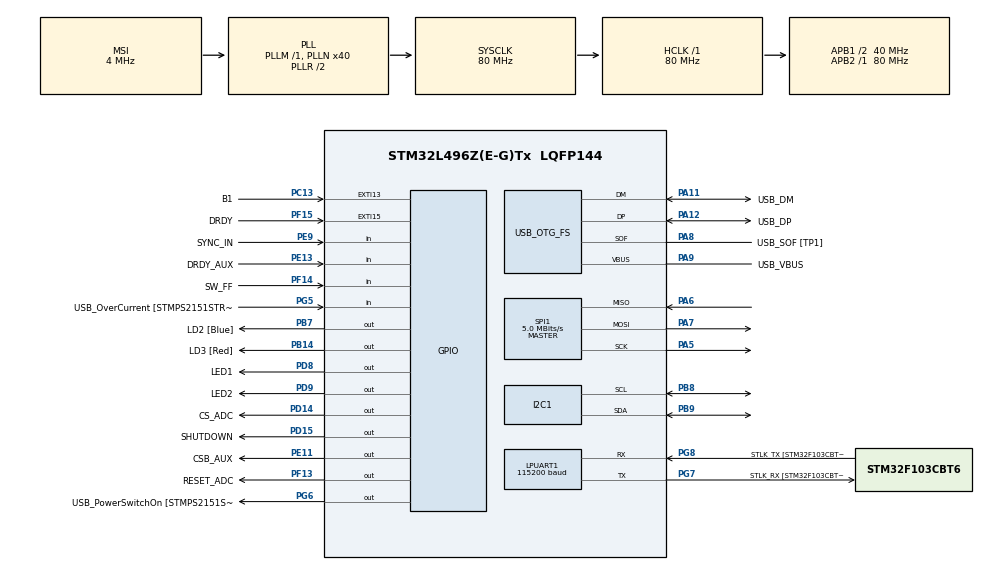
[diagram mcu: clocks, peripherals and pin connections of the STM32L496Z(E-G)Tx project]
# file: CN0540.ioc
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Dma.Request0=SPI1_RX
Dma.Request1=SPI1_TX
Dma.SPI1_RX.0.Direction=DMA_PERIPH_TO_MEMORY
Dma.SPI1_RX.0.Instance=DMA1_Channel2
Dma.SPI1_RX.0.MemDataAlignment=DMA_MDATAALIGN_BYTE
Dma.SPI1_RX.0.MemInc=DMA_MINC_ENABLE
Dma.SPI1_RX.0.Mode=DMA_NORMAL
Dma.SPI1_RX.0.PeriphDataAlignment=DMA_PDATAALIGN_BYTE
Dma.SPI1_RX.0.PeriphInc=DMA_PINC_DISABLE
Dma.SPI1_RX.0.Priority=DMA_PRIORITY_LOW
Dma.SPI1_TX.1.Direction=DMA_MEMORY_TO_PERIPH
Dma.SPI1_TX.1.Instance=DMA1_Channel3
Dma.SPI1_TX.1.MemDataAlignment=DMA_MDATAALIGN_BYTE
Dma.SPI1_TX.1.MemInc=DMA_MINC_ENABLE
Dma.SPI1_TX.1.Mode=DMA_NORMAL
Dma.SPI1_TX.1.PeriphDataAlignment=DMA_PDATAALIGN_BYTE
Dma.SPI1_TX.1.PeriphInc=DMA_PINC_DISABLE
Dma.SPI1_TX.1.Priority=DMA_PRIORITY_LOW
I2C1.Timing=0x00909BEB
LPUART1.BaudRate=115200
LPUART1.WordLength=UART_WORDLENGTH_8B
Mcu.Family=STM32L4
Mcu.Name=STM32L496Z(E-G)Tx
Mcu.Package=LQFP144
NVIC.DMA1_Channel2_IRQn=true\:0\:0\:false\:false\:true\:false\:true\:true
NVIC.DMA1_Channel3_IRQn=true\:0\:0\:false\:false\:true\:false\:true\:true
NVIC.EXTI15_10_IRQn=true\:0\:0\:false\:false\:true\:true\:true\:true
NVIC.I2C1_ER_IRQn=true\:0\:0\:false\:false\:true\:true\:true\:true
NVIC.I2C1_EV_IRQn=true\:0\:0\:false\:false\:true\:true\:true\:true
NVIC.LPUART1_IRQn=true\:0\:0\:false\:false\:true\:true\:true\:true
NVIC.PriorityGroup=NVIC_PRIORITYGROUP_4
PA10.GPIO_Label=USB_ID
PA10.Signal=USB_OTG_FS_ID
PA11.GPIO_Label=USB_DM
PA11.Mode=Device_Only
PA11.Signal=USB_OTG_FS_DM
PA12.GPIO_Label=USB_DP
PA12.Mode=Device_Only
PA12.Signal=USB_OTG_FS_DP
PA13\ (JTMS/SWDIO).GPIO_Label=TMS
PA13\ (JTMS/SWDIO).Mode=Trace_Asynchronous_SW
PA13\ (JTMS/SWDIO).Signal=SYS_JTMS-SWDIO
PA14\ (JTCK/SWCLK).GPIO_Label=TCK
PA14\ (JTCK/SWCLK).Mode=Trace_Asynchronous_SW
PA14\ (JTCK/SWCLK).Signal=SYS_JTCK-SWCLK
PA3.GPIO_Label=IO5
PA3.Signal=ADCx_IN8
PA5.GPIO_Speed=GPIO_SPEED_FREQ_HIGH
PA5.Mode=Full_Duplex_Master
PA5.Signal=SPI1_SCK
PA6.GPIO_Speed=GPIO_SPEED_FREQ_HIGH
PA6.Mode=Full_Duplex_Master
PA6.Signal=SPI1_MISO
PA7.GPIO_Speed=GPIO_SPEED_FREQ_HIGH
PA7.Mode=Full_Duplex_Master
PA7.Signal=SPI1_MOSI
PA8.GPIO_Label=USB_SOF [TP1]
PA8.Mode=Activate_SOF_FS
PA8.Signal=USB_OTG_FS_SOF
PA9.GPIO_Label=USB_VBUS
PA9.Mode=Activate_VBUS
PA9.Signal=USB_OTG_FS_VBUS
PB14.GPIO_Label=LD3 [Red]
PB14.Signal=GPIO_Output
PB3\ (JTDO/TRACESWO).GPIO_Label=SWO
PB3\ (JTDO/TRACESWO).Mode=Trace_Asynchronous_SW
PB3\ (JTDO/TRACESWO).Signal=SYS_JTDO-SWO
PB7.GPIO_Label=LD2 [Blue]
PB7.Signal=GPIO_Output
PB8.Mode=I2C
PB8.Signal=I2C1_SCL
PB9.Mode=I2C
PB9.Signal=I2C1_SDA
PC0.GPIO_Label=IO4
PC0.Signal=ADCx_IN1
PC13.GPIO_Label=B1
PC13.Signal=GPXTI13
PC14-OSC32_IN\ (PC14).Mode=LSE-External-Oscillator
PC14-OSC32_IN\ (PC14).Signal=RCC_OSC32_IN
PC15-OSC32_OUT\ (PC15).Mode=LSE-External-Oscillator
PC15-OSC32_OUT\ (PC15).Signal=RCC_OSC32_OUT
PC3.GPIO_Label=IO3
PC3.Signal=ADCx_IN4
PC5.GPIO_Label=IO0
PC5.Signal=ADCx_IN14
PD14.GPIO_Label=CS_ADC
PD14.PinState=GPIO_PIN_SET
PD14.Signal=GPIO_Output
PD15.GPIO_Label=SHUTDOWN
PD15.PinState=GPIO_PIN_SET
PD15.Signal=GPIO_Output
PD8.GPIO_Label=LED1
PD8.Signal=GPIO_Output
PD9.GPIO_Label=LED2
PD9.Signal=GPIO_Output
PE11.GPIO_Label=CSB_AUX
PE11.Signal=GPIO_Output
PE13.GPIO_Label=DRDY_AUX
PE13.Signal=GPIO_Input
PE9.GPIO_Label=SYNC_IN
PE9.Signal=GPIO_Input
PF13.GPIO_Label=RESET_ADC
PF13.GPIO_ModeDefaultOutputPP=GPIO_MODE_OUTPUT_OD
PF13.GPIO_PuPd=GPIO_NOPULL
PF13.PinState=GPIO_PIN_SET
PF13.Signal=GPIO_Output
PF14.GPIO_Label=SW_FF
PF14.Signal=GPIO_Input
PF15.GPIO_Label=DRDY
PF15.GPIO_ModeDefaultEXTI=GPIO_MODE_IT_FALLING
PF15.Signal=GPXTI15
PG5.GPIO_Label=USB_OverCurrent [STMPS2151STR_FAULT]
PG5.Signal=GPIO_Input
PG6.GPIO_Label=USB_PowerSwitchOn [STMPS2151STR_EN]
PG6.Signal=GPIO_Output
PG7.GPIO_Label=STLK_RX [STM32F103CBT6_PA3]
PG7.Mode=Asynchronous
PG7.Signal=LPUART1_TX
PG8.GPIO_Label=STLK_TX [STM32F103CBT6_PA2]
PG8.Mode=Asynchronous
PG8.Signal=LPUART1_RX
PH1-OSC_OUT\ (PH1).Signal=RCC_OSC_OUT
ProjectManager.HeapSize=0x200
ProjectManager.StackSize=0x400
ProjectManager.TargetToolchain=STM32CubeIDE
RCC.48MHZClocksFreq_Value=24000000
RCC.ADCFreq_Value=48000000
RCC.AHBFreq_Value=80000000
RCC.APB1CLKDivider=RCC_HCLK_DIV2
RCC.APB1Freq_Value=40000000
RCC.APB1TimFreq_Value=80000000
RCC.APB2Freq_Value=80000000
RCC.APB2TimFreq_Value=80000000
RCC.CortexFreq_Value=80000000
RCC.HCLKFreq_Value=80000000
RCC.HSE_VALUE=8000000
RCC.HSI48_VALUE=48000000
RCC.HSI_VALUE=16000000
RCC.MSI_VALUE=4000000
RCC.PLLMUL=RCC_PLL_MUL9
RCC.PLLN=40
RCC.PLLSAI1N=24
RCC.PRESCALERUSB=RCC_USBCLKSOURCE_PLL_DIV1_5
RCC.SYSCLKFreq_VALUE=80000000
RCC.SYSCLKSource=RCC_SYSCLKSOURCE_PLLCLK
RCC.SYSCLKSourceVirtual=RCC_SYSCLKSOURCE_PLLCLK
RCC.USBFreq_Value=48000000
RCC.VCOOutputFreq_Value=160000000
SH.ADCx_IN1.0=ADC1_IN1
SH.ADCx_IN14.0=ADC1_IN14
SH.ADCx_IN4.0=ADC1_IN4
SH.ADCx_IN8.0=ADC1_IN8
SPI1.BaudRatePrescaler=SPI_BAUDRATEPRESCALER_16
SPI1.CLKPhase=SPI_PHASE_2EDGE
SPI1.CLKPolarity=SPI_POLARITY_HIGH
SPI1.CalculateBaudRate=5.0 MBits/s
SPI1.DataSize=SPI_DATASIZE_8BIT
SPI1.Direction=SPI_DIRECTION_2LINES
SPI1.Mode=SPI_MODE_MASTER
SPI1.VirtualType=VM_MASTER
USB_OTG_FS.VirtualMode=Device_Only
VP_TIM3_VS_ClockSourceINT.Mode=Internal
board=NUCLEO-L496ZG

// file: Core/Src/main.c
/* USER CODE BEGIN Header */
/**
  ******************************************************************************
  * @file           : main.c
  * @brief          : Main program body
  ******************************************************************************
  * @attention
  *
  * Copyright (c) 2022 STMicroelectronics.
  * All rights reserved.
  *
  * This software is licensed under terms that can be found in the LICENSE file
  * in the root directory of this software component.
  * If no LICENSE file comes with this software, it is provided AS-IS.
  *
  ******************************************************************************
  */
/* USER CODE END Header */
#include "main.h"

/* USER CODE BEGIN Includes */
#include "cn0540_main.h"

/* USER CODE END Includes */

I2C_HandleTypeDef hi2c1;

SPI_HandleTypeDef hspi1;
DMA_HandleTypeDef hdma_spi1_rx;
DMA_HandleTypeDef hdma_spi1_tx;

PCD_HandleTypeDef hpcd_USB_OTG_FS;

void SystemClock_Config(void);
static void MX_GPIO_Init(void);
static void MX_DMA_Init(void);
static void MX_LPUART1_UART_Init(void);
static void MX_USB_OTG_FS_PCD_Init(void);
static void MX_I2C1_Init(void);
static void MX_SPI1_Init(void);
static void MX_TIM3_Init(void);

int main(void)
{

  /* MCU Configuration--------------------------------------------------------*/

  /* Reset of all peripherals, Initializes the Flash interface and the Systick. */
  HAL_Init();

  /* Configure the system clock */
  SystemClock_Config();

  /* Initialize all configured peripherals */
  MX_GPIO_Init();
  MX_DMA_Init();
  MX_LPUART1_UART_Init();
  MX_USB_OTG_FS_PCD_Init();
  MX_I2C1_Init();
  MX_SPI1_Init();
  MX_TIM3_Init();
  /* USER CODE BEGIN 2 */

  cn0540_main();

  /* USER CODE END 2 */

  /* Infinite loop */

}

void SystemClock_Config(void)
{
  RCC_OscInitTypeDef RCC_OscInitStruct = {0};
  RCC_ClkInitTypeDef RCC_ClkInitStruct = {0};

  /** Configure the main internal regulator output voltage
  */
  if (HAL_PWREx_ControlVoltageScaling(PWR_REGULATOR_VOLTAGE_SCALE1) != HAL_OK)
  {
    Error_Handler();
  }

  /** Configure LSE Drive Capability
  */
  HAL_PWR_EnableBkUpAccess();
  __HAL_RCC_LSEDRIVE_CONFIG(RCC_LSEDRIVE_LOW);

  /** Initializes the RCC Oscillators according to the specified parameters
  * in the RCC_OscInitTypeDef structure.
  */
  RCC_OscInitStruct.OscillatorType = RCC_OSCILLATORTYPE_LSE|RCC_OSCILLATORTYPE_MSI;
  RCC_OscInitStruct.LSEState = RCC_LSE_ON;
  RCC_OscInitStruct.MSIState = RCC_MSI_ON;
  RCC_OscInitStruct.MSICalibrationValue = 0;
  RCC_OscInitStruct.MSIClockRange = RCC_MSIRANGE_6;
  RCC_OscInitStruct.PLL.PLLState = RCC_PLL_ON;
  RCC_OscInitStruct.PLL.PLLSource = RCC_PLLSOURCE_MSI;
  RCC_OscInitStruct.PLL.PLLM = 1;
  RCC_OscInitStruct.PLL.PLLN = 40;
  RCC_OscInitStruct.PLL.PLLP = RCC_PLLP_DIV2;
  RCC_OscInitStruct.PLL.PLLQ = RCC_PLLQ_DIV2;
  RCC_OscInitStruct.PLL.PLLR = RCC_PLLR_DIV2;
  if (HAL_RCC_OscConfig(&RCC_OscInitStruct) != HAL_OK)
  {
    Error_Handler();
  }

  /** Initializes the CPU, AHB and APB buses clocks
  */
  RCC_ClkInitStruct.ClockType = RCC_CLOCKTYPE_HCLK|RCC_CLOCKTYPE_SYSCLK
                              |RCC_CLOCKTYPE_PCLK1|RCC_CLOCKTYPE_PCLK2;
  RCC_ClkInitStruct.SYSCLKSource = RCC_SYSCLKSOURCE_PLLCLK;
  RCC_ClkInitStruct.AHBCLKDivider = RCC_SYSCLK_DIV1;
  RCC_ClkInitStruct.APB1CLKDivider = RCC_HCLK_DIV2;
  RCC_ClkInitStruct.APB2CLKDivider = RCC_HCLK_DIV1;

  if (HAL_RCC_ClockConfig(&RCC_ClkInitStruct, FLASH_LATENCY_4) != HAL_OK)
  {
    Error_Handler();
  }

  /** Enable MSI Auto calibration
  */
  HAL_RCCEx_EnableMSIPLLMode();
}

static void MX_I2C1_Init(void)
{

  hi2c1.Instance = I2C1;
  hi2c1.Init.Timing = 0x00909BEB;
  hi2c1.Init.OwnAddress1 = 0;
  hi2c1.Init.AddressingMode = I2C_ADDRESSINGMODE_7BIT;
  hi2c1.Init.DualAddressMode = I2C_DUALADDRESS_DISABLE;
  hi2c1.Init.OwnAddress2 = 0;
  hi2c1.Init.OwnAddress2Masks = I2C_OA2_NOMASK;
  hi2c1.Init.GeneralCallMode = I2C_GENERALCALL_DISABLE;
  hi2c1.Init.NoStretchMode = I2C_NOSTRETCH_DISABLE;
  if (HAL_I2C_Init(&hi2c1) != HAL_OK)
  {
    Error_Handler();
  }

  /** Configure Analogue filter
  */
  if (HAL_I2CEx_ConfigAnalogFilter(&hi2c1, I2C_ANALOGFILTER_ENABLE) != HAL_OK)
  {
    Error_Handler();
  }

  /** Configure Digital filter
  */
  if (HAL_I2CEx_ConfigDigitalFilter(&hi2c1, 0) != HAL_OK)
  {
    Error_Handler();
  }

}

static void MX_LPUART1_UART_Init(void)
{

  LL_LPUART_InitTypeDef LPUART_InitStruct = {0};

  LL_GPIO_InitTypeDef GPIO_InitStruct = {0};
  RCC_PeriphCLKInitTypeDef PeriphClkInit = {0};

  /** Initializes the peripherals clock
  */
  PeriphClkInit.PeriphClockSelection = RCC_PERIPHCLK_LPUART1;
  PeriphClkInit.Lpuart1ClockSelection = RCC_LPUART1CLKSOURCE_PCLK1;
  if (HAL_RCCEx_PeriphCLKConfig(&PeriphClkInit) != HAL_OK)
  {
    Error_Handler();
  }

  /* Peripheral clock enable */
  LL_APB1_GRP2_EnableClock(LL_APB1_GRP2_PERIPH_LPUART1);

  LL_AHB2_GRP1_EnableClock(LL_AHB2_GRP1_PERIPH_GPIOG);
  HAL_PWREx_EnableVddIO2();
  /**LPUART1 GPIO Configuration
  PG7   ------> LPUART1_TX
  PG8   ------> LPUART1_RX
  */
  GPIO_InitStruct.Pin = LL_GPIO_PIN_7|LL_GPIO_PIN_8;
  GPIO_InitStruct.Mode = LL_GPIO_MODE_ALTERNATE;
  GPIO_InitStruct.Speed = LL_GPIO_SPEED_FREQ_VERY_HIGH;
  GPIO_InitStruct.OutputType = LL_GPIO_OUTPUT_PUSHPULL;
  GPIO_InitStruct.Pull = LL_GPIO_PULL_NO;
  GPIO_InitStruct.Alternate = LL_GPIO_AF_8;
  LL_GPIO_Init(GPIOG, &GPIO_InitStruct);

  /* LPUART1 interrupt Init */
  NVIC_SetPriority(LPUART1_IRQn, NVIC_EncodePriority(NVIC_GetPriorityGrouping(),0, 0));
  NVIC_EnableIRQ(LPUART1_IRQn);

  LPUART_InitStruct.BaudRate = 115200;
  LPUART_InitStruct.DataWidth = LL_LPUART_DATAWIDTH_8B;
  LPUART_InitStruct.StopBits = LL_LPUART_STOPBITS_1;
  LPUART_InitStruct.Parity = LL_LPUART_PARITY_NONE;
  LPUART_InitStruct.TransferDirection = LL_LPUART_DIRECTION_TX_RX;
  LPUART_InitStruct.HardwareFlowControl = LL_LPUART_HWCONTROL_NONE;
  LL_LPUART_Init(LPUART1, &LPUART_InitStruct);
  LL_LPUART_Enable(LPUART1);
  /* USER CODE BEGIN LPUART1_Init 2 */

  LL_LPUART_ClearFlag_PE(LPUART1);
  LL_LPUART_ClearFlag_FE(LPUART1);
  LL_LPUART_ClearFlag_NE(LPUART1);
  LL_LPUART_ClearFlag_ORE(LPUART1);
  LL_LPUART_EnableIT_RXNE(LPUART1);

  /* USER CODE END LPUART1_Init 2 */

}

static void MX_SPI1_Init(void)
{

  /* SPI1 parameter configuration*/
  hspi1.Instance = SPI1;
  hspi1.Init.Mode = SPI_MODE_MASTER;
  hspi1.Init.Direction = SPI_DIRECTION_2LINES;
  hspi1.Init.DataSize = SPI_DATASIZE_8BIT;
  hspi1.Init.CLKPolarity = SPI_POLARITY_HIGH;
  hspi1.Init.CLKPhase = SPI_PHASE_2EDGE;
  hspi1.Init.NSS = SPI_NSS_SOFT;
  hspi1.Init.BaudRatePrescaler = SPI_BAUDRATEPRESCALER_16;
  hspi1.Init.FirstBit = SPI_FIRSTBIT_MSB;
  hspi1.Init.TIMode = SPI_TIMODE_DISABLE;
  hspi1.Init.CRCCalculation = SPI_CRCCALCULATION_DISABLE;
  hspi1.Init.CRCPolynomial = 7;
  hspi1.Init.CRCLength = SPI_CRC_LENGTH_DATASIZE;
  hspi1.Init.NSSPMode = SPI_NSS_PULSE_DISABLE;
  if (HAL_SPI_Init(&hspi1) != HAL_OK)
  {
    Error_Handler();
  }

}

static void MX_TIM3_Init(void)
{

  LL_TIM_InitTypeDef TIM_InitStruct = {0};

  /* Peripheral clock enable */
  LL_APB1_GRP1_EnableClock(LL_APB1_GRP1_PERIPH_TIM3);

  TIM_InitStruct.Prescaler = 0;
  TIM_InitStruct.CounterMode = LL_TIM_COUNTERMODE_UP;
  TIM_InitStruct.Autoreload = 65535;
  TIM_InitStruct.ClockDivision = LL_TIM_CLOCKDIVISION_DIV1;
  LL_TIM_Init(TIM3, &TIM_InitStruct);
  LL_TIM_DisableARRPreload(TIM3);
  LL_TIM_SetClockSource(TIM3, LL_TIM_CLOCKSOURCE_INTERNAL);
  LL_TIM_SetTriggerOutput(TIM3, LL_TIM_TRGO_RESET);
  LL_TIM_DisableMasterSlaveMode(TIM3);

}

static void MX_USB_OTG_FS_PCD_Init(void)
{

  hpcd_USB_OTG_FS.Instance = USB_OTG_FS;
  hpcd_USB_OTG_FS.Init.dev_endpoints = 6;
  hpcd_USB_OTG_FS.Init.speed = PCD_SPEED_FULL;
  hpcd_USB_OTG_FS.Init.phy_itface = PCD_PHY_EMBEDDED;
  hpcd_USB_OTG_FS.Init.Sof_enable = ENABLE;
  hpcd_USB_OTG_FS.Init.low_power_enable = DISABLE;
  hpcd_USB_OTG_FS.Init.lpm_enable = DISABLE;
  hpcd_USB_OTG_FS.Init.battery_charging_enable = ENABLE;
  hpcd_USB_OTG_FS.Init.use_dedicated_ep1 = DISABLE;
  hpcd_USB_OTG_FS.Init.vbus_sensing_enable = ENABLE;
  if (HAL_PCD_Init(&hpcd_USB_OTG_FS) != HAL_OK)
  {
    Error_Handler();
  }

}

static void MX_DMA_Init(void)
{

  /* DMA controller clock enable */
  __HAL_RCC_DMA1_CLK_ENABLE();

  /* DMA interrupt init */
  /* DMA1_Channel2_IRQn interrupt configuration */
  HAL_NVIC_SetPriority(DMA1_Channel2_IRQn, 0, 0);
  HAL_NVIC_EnableIRQ(DMA1_Channel2_IRQn);
  /* DMA1_Channel3_IRQn interrupt configuration */
  HAL_NVIC_SetPriority(DMA1_Channel3_IRQn, 0, 0);
  HAL_NVIC_EnableIRQ(DMA1_Channel3_IRQn);

}

static void MX_GPIO_Init(void)
{
  GPIO_InitTypeDef GPIO_InitStruct = {0};

  /* GPIO Ports Clock Enable */
  __HAL_RCC_GPIOE_CLK_ENABLE();
  __HAL_RCC_GPIOC_CLK_ENABLE();
  __HAL_RCC_GPIOF_CLK_ENABLE();
  __HAL_RCC_GPIOH_CLK_ENABLE();
  __HAL_RCC_GPIOA_CLK_ENABLE();
  __HAL_RCC_GPIOB_CLK_ENABLE();
  __HAL_RCC_GPIOG_CLK_ENABLE();
  __HAL_RCC_GPIOD_CLK_ENABLE();
  HAL_PWREx_EnableVddIO2();

  /*Configure GPIO pin Output Level */
  HAL_GPIO_WritePin(RESET_ADC_GPIO_Port, RESET_ADC_Pin, GPIO_PIN_SET);

  /*Configure GPIO pin Output Level */
  HAL_GPIO_WritePin(CSB_AUX_GPIO_Port, CSB_AUX_Pin, GPIO_PIN_RESET);

  /*Configure GPIO pin Output Level */
  HAL_GPIO_WritePin(GPIOB, LD3_Pin|LD2_Pin, GPIO_PIN_RESET);

  /*Configure GPIO pin Output Level */
  HAL_GPIO_WritePin(GPIOD, LED1_Pin|LED2_Pin, GPIO_PIN_RESET);

  /*Configure GPIO pin Output Level */
  HAL_GPIO_WritePin(GPIOD, CS_ADC_Pin|SHUTDOWN_Pin, GPIO_PIN_SET);

  /*Configure GPIO pin Output Level */
  HAL_GPIO_WritePin(USB_PowerSwitchOn_GPIO_Port, USB_PowerSwitchOn_Pin, GPIO_PIN_RESET);

  /*Configure GPIO pins : PE2 PE3 PE4 PE5
                           PE6 PE7 PE8 PE10
                           PE12 PE14 PE15 PE0
                           PE1 */
  GPIO_InitStruct.Pin = GPIO_PIN_2|GPIO_PIN_3|GPIO_PIN_4|GPIO_PIN_5
                          |GPIO_PIN_6|GPIO_PIN_7|GPIO_PIN_8|GPIO_PIN_10
                          |GPIO_PIN_12|GPIO_PIN_14|GPIO_PIN_15|GPIO_PIN_0
                          |GPIO_PIN_1;
  GPIO_InitStruct.Mode = GPIO_MODE_ANALOG;
  GPIO_InitStruct.Pull = GPIO_NOPULL;
  HAL_GPIO_Init(GPIOE, &GPIO_InitStruct);

  /*Configure GPIO pin : B1_Pin */
  GPIO_InitStruct.Pin = B1_Pin;
  GPIO_InitStruct.Mode = GPIO_MODE_IT_RISING;
  GPIO_InitStruct.Pull = GPIO_NOPULL;
  HAL_GPIO_Init(B1_GPIO_Port, &GPIO_InitStruct);

  /*Configure GPIO pins : PF0 PF1 PF2 PF3
                           PF4 PF5 PF6 PF7
                           PF8 PF9 PF10 PF11
                           PF12 */
  GPIO_InitStruct.Pin = GPIO_PIN_0|GPIO_PIN_1|GPIO_PIN_2|GPIO_PIN_3
                          |GPIO_PIN_4|GPIO_PIN_5|GPIO_PIN_6|GPIO_PIN_7
                          |GPIO_PIN_8|GPIO_PIN_9|GPIO_PIN_10|GPIO_PIN_11
                          |GPIO_PIN_12;
  GPIO_InitStruct.Mode = GPIO_MODE_ANALOG;
  GPIO_InitStruct.Pull = GPIO_NOPULL;
  HAL_GPIO_Init(GPIOF, &GPIO_InitStruct);

  /*Configure GPIO pins : PH0 PH3 */
  GPIO_InitStruct.Pin = GPIO_PIN_0|GPIO_PIN_3;
  GPIO_InitStruct.Mode = GPIO_MODE_ANALOG;
  GPIO_InitStruct.Pull = GPIO_NOPULL;
  HAL_GPIO_Init(GPIOH, &GPIO_InitStruct);

  /*Configure GPIO pins : IO4_Pin PC1 PC2 IO3_Pin
                           PC4 IO0_Pin PC6 PC7
                           PC8 PC9 PC10 PC11
                           PC12 */
  GPIO_InitStruct.Pin = IO4_Pin|GPIO_PIN_1|GPIO_PIN_2|IO3_Pin
                          |GPIO_PIN_4|IO0_Pin|GPIO_PIN_6|GPIO_PIN_7
                          |GPIO_PIN_8|GPIO_PIN_9|GPIO_PIN_10|GPIO_PIN_11
                          |GPIO_PIN_12;
  GPIO_InitStruct.Mode = GPIO_MODE_ANALOG;
  GPIO_InitStruct.Pull = GPIO_NOPULL;
  HAL_GPIO_Init(GPIOC, &GPIO_InitStruct);

  /*Configure GPIO pins : PA0 PA1 PA2 IO5_Pin
                           PA4 PA15 */
  GPIO_InitStruct.Pin = GPIO_PIN_0|GPIO_PIN_1|GPIO_PIN_2|IO5_Pin
                          |GPIO_PIN_4|GPIO_PIN_15;
  GPIO_InitStruct.Mode = GPIO_MODE_ANALOG;
  GPIO_InitStruct.Pull = GPIO_NOPULL;
  HAL_GPIO_Init(GPIOA, &GPIO_InitStruct);

  /*Configure GPIO pins : PB0 PB1 PB2 PB10
                           PB11 PB12 PB13 PB15
                           PB4 PB5 PB6 */
  GPIO_InitStruct.Pin = GPIO_PIN_0|GPIO_PIN_1|GPIO_PIN_2|GPIO_PIN_10
                          |GPIO_PIN_11|GPIO_PIN_12|GPIO_PIN_13|GPIO_PIN_15
                          |GPIO_PIN_4|GPIO_PIN_5|GPIO_PIN_6;
  GPIO_InitStruct.Mode = GPIO_MODE_ANALOG;
  GPIO_InitStruct.Pull = GPIO_NOPULL;
  HAL_GPIO_Init(GPIOB, &GPIO_InitStruct);

  /*Configure GPIO pin : RESET_ADC_Pin */
  GPIO_InitStruct.Pin = RESET_ADC_Pin;
  GPIO_InitStruct.Mode = GPIO_MODE_OUTPUT_OD;
  GPIO_InitStruct.Pull = GPIO_NOPULL;
  GPIO_InitStruct.Speed = GPIO_SPEED_FREQ_LOW;
  HAL_GPIO_Init(RESET_ADC_GPIO_Port, &GPIO_InitStruct);

  /*Configure GPIO pin : SW_FF_Pin */
  GPIO_InitStruct.Pin = SW_FF_Pin;
  GPIO_InitStruct.Mode = GPIO_MODE_INPUT;
  GPIO_InitStruct.Pull = GPIO_NOPULL;
  HAL_GPIO_Init(SW_FF_GPIO_Port, &GPIO_InitStruct);

  /*Configure GPIO pin : DRDY_Pin */
  GPIO_InitStruct.Pin = DRDY_Pin;
  GPIO_InitStruct.Mode = GPIO_MODE_IT_FALLING;
  GPIO_InitStruct.Pull = GPIO_NOPULL;
  HAL_GPIO_Init(DRDY_GPIO_Port, &GPIO_InitStruct);

  /*Configure GPIO pins : PG0 PG1 PG2 PG3
                           PG4 PG9 PG10 PG11
                           PG12 PG13 PG14 PG15 */
  GPIO_InitStruct.Pin = GPIO_PIN_0|GPIO_PIN_1|GPIO_PIN_2|GPIO_PIN_3
                          |GPIO_PIN_4|GPIO_PIN_9|GPIO_PIN_10|GPIO_PIN_11
                          |GPIO_PIN_12|GPIO_PIN_13|GPIO_PIN_14|GPIO_PIN_15;
  GPIO_InitStruct.Mode = GPIO_MODE_ANALOG;
  GPIO_InitStruct.Pull = GPIO_NOPULL;
  HAL_GPIO_Init(GPIOG, &GPIO_InitStruct);

  /*Configure GPIO pins : SYNC_IN_Pin DRDY_AUX_Pin */
  GPIO_InitStruct.Pin = SYNC_IN_Pin|DRDY_AUX_Pin;
  GPIO_InitStruct.Mode = GPIO_MODE_INPUT;
  GPIO_InitStruct.Pull = GPIO_NOPULL;
  HAL_GPIO_Init(GPIOE, &GPIO_InitStruct);

  /*Configure GPIO pin : CSB_AUX_Pin */
  GPIO_InitStruct.Pin = CSB_AUX_Pin;
  GPIO_InitStruct.Mode = GPIO_MODE_OUTPUT_PP;
  GPIO_InitStruct.Pull = GPIO_NOPULL;
  GPIO_InitStruct.Speed = GPIO_SPEED_FREQ_LOW;
  HAL_GPIO_Init(CSB_AUX_GPIO_Port, &GPIO_InitStruct);

  /*Configure GPIO pins : LD3_Pin LD2_Pin */
  GPIO_InitStruct.Pin = LD3_Pin|LD2_Pin;
  GPIO_InitStruct.Mode = GPIO_MODE_OUTPUT_PP;
  GPIO_InitStruct.Pull = GPIO_NOPULL;
  GPIO_InitStruct.Speed = GPIO_SPEED_FREQ_LOW;
  HAL_GPIO_Init(GPIOB, &GPIO_InitStruct);

  /*Configure GPIO pins : LED1_Pin LED2_Pin CS_ADC_Pin SHUTDOWN_Pin */
  GPIO_InitStruct.Pin = LED1_Pin|LED2_Pin|CS_ADC_Pin|SHUTDOWN_Pin;
  GPIO_InitStruct.Mode = GPIO_MODE_OUTPUT_PP;
  GPIO_InitStruct.Pull = GPIO_NOPULL;
  GPIO_InitStruct.Speed = GPIO_SPEED_FREQ_LOW;
  HAL_GPIO_Init(GPIOD, &GPIO_InitStruct);

  /*Configure GPIO pins : PD10 PD11 PD12 PD13
                           PD0 PD1 PD2 PD3
                           PD4 PD5 PD6 PD7 */
  GPIO_InitStruct.Pin = GPIO_PIN_10|GPIO_PIN_11|GPIO_PIN_12|GPIO_PIN_13
                          |GPIO_PIN_0|GPIO_PIN_1|GPIO_PIN_2|GPIO_PIN_3
                          |GPIO_PIN_4|GPIO_PIN_5|GPIO_PIN_6|GPIO_PIN_7;
  GPIO_InitStruct.Mode = GPIO_MODE_ANALOG;
  GPIO_InitStruct.Pull = GPIO_NOPULL;
  HAL_GPIO_Init(GPIOD, &GPIO_InitStruct);

  /*Configure GPIO pin : USB_OverCurrent_Pin */
  GPIO_InitStruct.Pin = USB_OverCurrent_Pin;
  GPIO_InitStruct.Mode = GPIO_MODE_INPUT;
  GPIO_InitStruct.Pull = GPIO_NOPULL;
  HAL_GPIO_Init(USB_OverCurrent_GPIO_Port, &GPIO_InitStruct);

  /*Configure GPIO pin : USB_PowerSwitchOn_Pin */
  GPIO_InitStruct.Pin = USB_PowerSwitchOn_Pin;
  GPIO_InitStruct.Mode = GPIO_MODE_OUTPUT_PP;
  GPIO_InitStruct.Pull = GPIO_NOPULL;
  GPIO_InitStruct.Speed = GPIO_SPEED_FREQ_LOW;
  HAL_GPIO_Init(USB_PowerSwitchOn_GPIO_Port, &GPIO_InitStruct);

  /* EXTI interrupt init*/
  HAL_NVIC_SetPriority(EXTI15_10_IRQn, 0, 0);
  HAL_NVIC_EnableIRQ(EXTI15_10_IRQn);

}

void Error_Handler(void)
{
  __disable_irq();
  while (1)
  {
  }
}

#ifdef  USE_FULL_ASSERT
/**
  * @brief  Reports the name of the source file and the source line number
  *         where the assert_param error has occurred.
  * @param  file: pointer to the source file name
  * @param  line: assert_param error line source number
  * @retval None
  */
void assert_failed(uint8_t *file, uint32_t line)
{
  /* USER CODE BEGIN 6 */
  /* User can add his own implementation to report the file name and line number,
     ex: printf_("Wrong parameters value: file %s on line %d\r\n", file, line) */
	(void)file;
	(void)line;
  /* USER CODE END 6 */
}
#endif /* USE_FULL_ASSERT */
